# LargeDummyDevice register map
File version: 1.0
Registers are 32-bit, read-write, no defined reset value unless marked. A register's access mark holds for its fields unless they carry their own. Offsets are from the block's base; [hi:lo] are bit positions.

## PERIPHERAL_72
Base 0x40047000
0x04 REG_1 — Register 1
  [33:30] FIELD_1, [29:26] FIELD_8, [23:22] FIELD_6, [24:22] FIELD_7, [21] FIELD_4, [13] FIELD_9, [12:11] FIELD_10, [12:9] FIELD_3, [8:4] FIELD_2, [7:3] FIELD_5
0x08 REG_2 — Register 2
  [35:31] FIELD_5, [27] FIELD_8, [16:15] FIELD_4, [18:14] FIELD_10, [11:9] FIELD_1, [8] FIELD_3, [8:5] FIELD_9, [5:3] FIELD_6, [5:2] FIELD_11, [2:1] FIELD_7, [1:0] FIELD_2
0x0C REG_3 — Register 3
  [34:31] FIELD_7, [31:30] FIELD_5, [32:28] FIELD_1, [24] FIELD_9, [25:23] FIELD_12, [23:21] FIELD_2, [23:21] FIELD_4, [16] FIELD_6, [17:16] FIELD_10, [6:3] FIELD_3, [7:3] FIELD_11, [5:1] FIELD_8
0x10 REG_4 — Register 4
  [27] FIELD_5, [27:25] FIELD_13, [23:21] FIELD_15, [18:14] FIELD_3, [17:13] FIELD_12, [16:12] FIELD_14, [11] FIELD_1, [13:11] FIELD_7, [13:11] FIELD_8, [14:11] FIELD_9, [13:10] FIELD_6, [10:8] FIELD_2, [11:7] FIELD_10, [8:4] FIELD_11, [4:1] FIELD_4
0x14 REG_5 — Register 5
  [32:29] FIELD_3, [32:28] FIELD_6, [30:28] FIELD_11, [29:27] FIELD_12, [28:27] FIELD_19, [28:26] FIELD_8, [23] FIELD_14, [25:23] FIELD_16, [23:20] FIELD_5, [21:20] FIELD_7, [20] FIELD_17, [22:18] FIELD_2, [18] FIELD_15, [19:17] FIELD_13, [14:13] FIELD_21, [14:12] FIELD_1, [14:11] FIELD_4, [11] FIELD_10, [9:8] FIELD_18, [8] FIELD_20, [7:6] FIELD_9
0x18 REG_6 — Register 6
  [34:30] FIELD_8, [33:30] FIELD_12, [33:30] FIELD_13, [32:30] FIELD_16, [31:30] FIELD_24, [30:29] FIELD_4, [32:29] FIELD_5, [28:27] FIELD_9, [27] FIELD_18, [23] FIELD_25, [23:21] FIELD_1, [23:21] FIELD_14, [20:19] FIELD_23, [18] FIELD_11, [20:17] FIELD_2, [17] FIELD_15, [18:16] FIELD_21, [14] FIELD_22, [11:8] FIELD_17, [9:8] FIELD_19, [7:4] FIELD_26, [7:4] FIELD_27, [7:3] FIELD_3, [7:3] FIELD_6, [4:3] FIELD_10, [5:2] FIELD_20, [2:1] FIELD_7
0x1C REG_7 — Register 7
  [33:31] FIELD_4, [25] FIELD_7, [22:18] FIELD_3, [17:14] FIELD_8, [13] FIELD_1, [6:4] FIELD_2, [3:1] FIELD_5, [5:1] FIELD_6
0x20 REG_8 — Register 8
  [33:30] FIELD_7, [30] FIELD_16, [25:24] FIELD_9, [27:23] FIELD_15, [21:20] FIELD_27, [21:19] FIELD_6, [22:19] FIELD_14, [22:18] FIELD_2, [19:18] FIELD_23, [19:15] FIELD_5, [17:15] FIELD_8, [16:15] FIELD_28, [14] FIELD_1, [17:13] FIELD_11, [15:13] FIELD_21, [12:10] FIELD_19, [11:10] FIELD_20, [13:9] FIELD_13, [9] FIELD_24, [12:8] FIELD_3, [8] FIELD_4, [11:7] FIELD_17, [6:5] FIELD_18, [5] FIELD_25, [7:3] FIELD_22, [3:0] FIELD_10, [1:0] FIELD_12, [4:0] FIELD_26
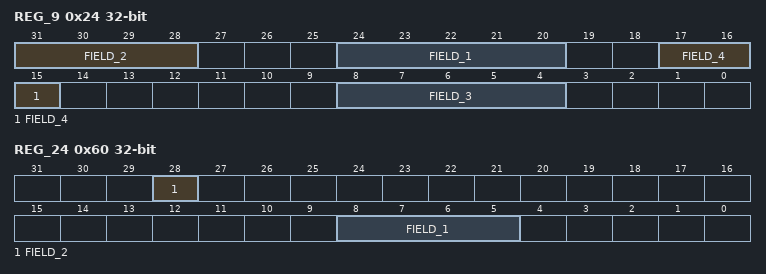
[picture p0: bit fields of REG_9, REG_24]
0x24 REG_9 — Register 9
  [31:28] FIELD_2, [24:20] FIELD_1, [17:15] FIELD_4, [8:4] FIELD_3
0x28 REG_10 — Register 10
  [30] FIELD_4, [26] FIELD_3, [27:26] FIELD_9, [30:26] FIELD_10, [26:24] FIELD_8, [24:23] FIELD_2, [9:8] FIELD_1, [5] FIELD_6, [6:4] FIELD_5, [1:0] FIELD_7
0x2C REG_11 — Register 11
  [33:29] FIELD_4, [27:25] FIELD_1, [23] FIELD_11, [22] FIELD_14, [21:20] FIELD_8, [21:18] FIELD_16, [16] FIELD_3, [18:16] FIELD_6, [17:15] FIELD_12, [11:8] FIELD_7, [9:6] FIELD_9, [6:5] FIELD_5, [8:5] FIELD_10, [5:4] FIELD_2, [5:3] FIELD_13, [7:3] FIELD_15, [4:1] FIELD_17
0x30 REG_12 — Register 12
  [34:30] FIELD_3, [30:27] FIELD_4, [20:17] FIELD_2, [9:8] FIELD_1
0x34 REG_13 — Register 13
  [14:13] FIELD_1
0x38 REG_14 — Register 14
  [32:30] FIELD_14, [32:30] FIELD_19, [28] FIELD_20, [28:27] FIELD_4, [28:26] FIELD_5, [27:23] FIELD_13, [23:22] FIELD_3, [25:22] FIELD_17, [21:19] FIELD_18, [20:17] FIELD_12, [16] FIELD_6, [9:8] FIELD_8, [10:8] FIELD_15, [7:5] FIELD_1, [9:5] FIELD_11, [9:5] FIELD_21, [4] FIELD_10, [6:3] FIELD_7, [5:2] FIELD_9, [5:2] FIELD_16, [2:0] FIELD_2
0x3C REG_15 — Register 15
  [30] FIELD_11, [30:29] FIELD_14, [31:27] FIELD_13, [29:26] FIELD_1, [27:25] FIELD_5, [24] FIELD_8, [27:24] FIELD_12, [25:23] FIELD_7, [25:23] FIELD_10, [24:20] FIELD_9, [20:19] FIELD_2, [14:12] FIELD_3, [8:6] FIELD_6, [3] FIELD_4
0x40 REG_16 — Register 16
  [33:31] FIELD_16, [31] FIELD_19, [33:30] FIELD_11, [32:30] FIELD_23, [29:25] FIELD_27, [27:24] FIELD_17, [26:22] FIELD_5, [25:22] FIELD_8, [22] FIELD_12, [20] FIELD_24, [23:19] FIELD_22, [23:19] FIELD_29, [20:17] FIELD_4, [19:16] FIELD_21, [19:15] FIELD_1, [14] FIELD_20, [13:12] FIELD_15, [12:11] FIELD_2, [14:11] FIELD_6, [12:11] FIELD_10, [13:11] FIELD_13, [8] FIELD_14, [7] FIELD_26, [8:6] FIELD_18, [5] FIELD_3, [7:5] FIELD_9, [7:5] FIELD_28, [7:4] FIELD_7, [4] FIELD_25
0x44 REG_17 — Register 17
  [33:30] FIELD_21, [32:29] FIELD_27, [29] FIELD_28, [27:26] FIELD_10, [26:25] FIELD_24, [27:24] FIELD_11, [26:23] FIELD_9, [23:22] FIELD_7, [23:22] FIELD_22, [22:21] FIELD_14, [20] FIELD_26, [20:19] FIELD_18, [18] FIELD_1, [21:18] FIELD_2, [20:17] FIELD_3, [20:16] FIELD_13, [15:14] FIELD_12, [15:11] FIELD_4, [13:10] FIELD_25, [9:8] FIELD_8, [12:8] FIELD_16, [10:7] FIELD_6, [8:7] FIELD_20, [9:5] FIELD_15, [7:5] FIELD_19, [6:2] FIELD_5, [4:2] FIELD_23, [1:0] FIELD_17
0x48 REG_18 — Register 18
  [32:30] FIELD_21, [34:30] FIELD_22, [29] FIELD_10, [33:29] FIELD_20, [26:25] FIELD_8, [26:24] FIELD_16, [23:19] FIELD_9, [19:18] FIELD_29, [17:16] FIELD_15, [20:16] FIELD_18, [15] FIELD_7, [15] FIELD_19, [14] FIELD_2, [17:14] FIELD_28, [11] FIELD_26, [10] FIELD_24, [13:9] FIELD_11, [12:9] FIELD_13, [8] FIELD_25, [9:7] FIELD_4, [11:7] FIELD_5, [10:7] FIELD_6, [10:6] FIELD_3, [8:6] FIELD_27, [8:4] FIELD_14, [5:4] FIELD_23, [4:3] FIELD_1, [2:0] FIELD_12, [4:0] FIELD_17
0x4C REG_19 — Register 19
  [32:31] FIELD_3, [35:31] FIELD_12, [29] FIELD_20, [24] FIELD_21, [24:23] FIELD_6, [23:22] FIELD_7, [17:16] FIELD_14, [16:15] FIELD_16, [15] FIELD_23, [12] FIELD_4, [15:11] FIELD_10, [11:10] FIELD_1, [14:10] FIELD_11, [14:10] FIELD_22, [12:8] FIELD_2, [9:7] FIELD_13, [7] FIELD_15, [8:7] FIELD_19, [6] FIELD_5, [7:5] FIELD_8, [4:3] FIELD_9, [5:2] FIELD_18, [5:2] FIELD_24, [4:0] FIELD_17
0x50 REG_20 — Register 20
  [31] FIELD_24, [32:29] FIELD_3, [29] FIELD_13, [30:29] FIELD_15, [31:28] FIELD_10, [31:27] FIELD_9, [25] FIELD_26, [27:23] FIELD_2, [21] FIELD_4, [23:21] FIELD_12, [21:20] FIELD_1, [20] FIELD_11, [21:19] FIELD_14, [23:19] FIELD_22, [21:17] FIELD_8, [16:15] FIELD_7, [17:13] FIELD_17, [15:12] FIELD_16, [12] FIELD_23, [9] FIELD_20, [9:8] FIELD_19, [11:8] FIELD_25, [8:6] FIELD_18, [6:3] FIELD_6, [5:2] FIELD_5, [4:0] FIELD_21
0x54 REG_21 — Register 21
  [32:29] FIELD_5, [23] FIELD_3, [22:20] FIELD_4, [17:16] FIELD_1, [18:16] FIELD_2, [15:13] FIELD_12, [10:9] FIELD_10, [10:8] FIELD_8, [7:6] FIELD_6, [10:6] FIELD_9, [5] FIELD_7, [7:4] FIELD_11
0x58 REG_22 — Register 22
  [31:29] FIELD_18, [30:28] FIELD_4, [32:28] FIELD_10, [29:28] FIELD_25, [28:27] FIELD_7, [31:27] FIELD_19, [26] FIELD_16, [25] FIELD_8, [25:22] FIELD_13, [22] FIELD_23, [25:21] FIELD_5, [23:21] FIELD_17, [18:17] FIELD_1, [16:14] FIELD_14, [17:13] FIELD_11, [9] FIELD_20, [7] FIELD_3, [7] FIELD_9, [11:7] FIELD_26, [5:4] FIELD_15, [8:4] FIELD_21, [8:4] FIELD_24, [4:3] FIELD_6, [3] FIELD_12, [3] FIELD_22, [2] FIELD_2
0x5C REG_23 — Register 23
  [31] FIELD_26, [31:29] FIELD_23, [28:27] FIELD_13, [25] FIELD_7, [26:23] FIELD_5, [26:22] FIELD_8, [26:22] FIELD_19, [22:21] FIELD_14, [20] FIELD_11, [19:18] FIELD_4, [15] FIELD_3, [19:15] FIELD_16, [12] FIELD_10, [12] FIELD_25, [14:11] FIELD_2, [13:11] FIELD_17, [10] FIELD_22, [12:8] FIELD_18, [11:7] FIELD_9, [8:7] FIELD_12, [7] FIELD_15, [10:6] FIELD_20, [8:5] FIELD_24, [5:4] FIELD_6, [4:1] FIELD_1, [0] FIELD_21
0x60 REG_24 — Register 24
  [28] FIELD_2, [8:5] FIELD_1
0x64 REG_25 — Register 25
  [31:28] FIELD_2, [29:27] FIELD_12, [30:26] FIELD_6, [26:23] FIELD_10, [27:23] FIELD_13, [23:22] FIELD_8, [19:18] FIELD_4, [16] FIELD_15, [18:14] FIELD_5, [15:12] FIELD_16, [11] FIELD_9, [11:10] FIELD_1, [11:7] FIELD_3, [6:5] FIELD_7, [5:3] FIELD_11, [2:1] FIELD_14
0x68 REG_26 — Register 26
  [33:31] FIELD_11, [34:31] FIELD_29, [33:31] FIELD_30, [30:29] FIELD_26, [28:26] FIELD_9, [30:26] FIELD_10, [26:25] FIELD_2, [25:23] FIELD_4, [24:23] FIELD_20, [21:20] FIELD_1, [20] FIELD_28, [22:19] FIELD_18, [17] FIELD_22, [17:16] FIELD_21, [15] FIELD_3, [16:15] FIELD_12, [18:14] FIELD_17, [14] FIELD_24, [12:11] FIELD_5, [10:9] FIELD_6, [13:9] FIELD_7, [7] FIELD_25, [8:6] FIELD_15, [7:5] FIELD_23, [6:4] FIELD_19, [6:3] FIELD_8, [6:2] FIELD_13, [5:2] FIELD_14, [5:1] FIELD_16, [1] FIELD_27
0x6C REG_27 — Register 27
  [34:30] FIELD_27, [24] FIELD_11, [22:21] FIELD_1, [25:21] FIELD_8, [24:20] FIELD_6, [23:20] FIELD_23, [22:18] FIELD_4, [17:16] FIELD_17, [19:15] FIELD_5, [18:15] FIELD_22, [14] FIELD_19, [13] FIELD_18, [13:11] FIELD_15, [11] FIELD_24, [11:10] FIELD_2, [10] FIELD_20, [10:8] FIELD_3, [8] FIELD_7, [10:8] FIELD_13, [8] FIELD_21, [7] FIELD_14, [9:7] FIELD_25, [6] FIELD_12, [8:5] FIELD_10, [7:4] FIELD_16, [4:0] FIELD_9, [0] FIELD_26
0x70 REG_28 — Register 28
  [34:31] FIELD_15, [32:31] FIELD_16, [29:26] FIELD_8, [27:25] FIELD_14, [28:25] FIELD_17, [27:23] FIELD_13, [24:21] FIELD_9, [20] FIELD_2, [20:19] FIELD_4, [19] FIELD_5, [18:16] FIELD_12, [16:15] FIELD_11, [13:9] FIELD_6, [3] FIELD_1, [4:3] FIELD_7, [3:0] FIELD_3, [0] FIELD_10
0x74 REG_29 — Register 29
  [29:25] FIELD_3, [23] FIELD_8, [19:17] FIELD_1, [12:11] FIELD_2, [11:7] FIELD_4, [8:7] FIELD_9, [10:6] FIELD_6, [3:1] FIELD_7, [0] FIELD_5
